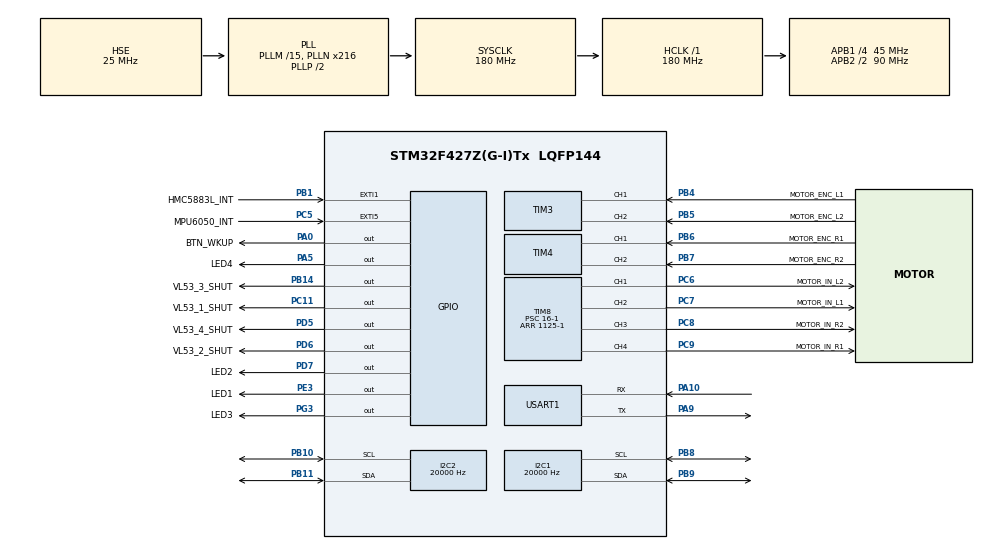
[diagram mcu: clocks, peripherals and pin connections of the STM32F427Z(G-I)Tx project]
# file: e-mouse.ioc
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Dma.I2C1_RX.4.Direction=DMA_PERIPH_TO_MEMORY
Dma.I2C1_RX.4.FIFOMode=DMA_FIFOMODE_DISABLE
Dma.I2C1_RX.4.Instance=DMA1_Stream0
Dma.I2C1_RX.4.MemDataAlignment=DMA_MDATAALIGN_BYTE
Dma.I2C1_RX.4.MemInc=DMA_MINC_ENABLE
Dma.I2C1_RX.4.Mode=DMA_NORMAL
Dma.I2C1_RX.4.PeriphDataAlignment=DMA_PDATAALIGN_BYTE
Dma.I2C1_RX.4.PeriphInc=DMA_PINC_DISABLE
Dma.I2C1_RX.4.Priority=DMA_PRIORITY_HIGH
Dma.I2C1_TX.5.Direction=DMA_MEMORY_TO_PERIPH
Dma.I2C1_TX.5.FIFOMode=DMA_FIFOMODE_DISABLE
Dma.I2C1_TX.5.Instance=DMA1_Stream6
Dma.I2C1_TX.5.MemDataAlignment=DMA_MDATAALIGN_BYTE
Dma.I2C1_TX.5.MemInc=DMA_MINC_ENABLE
Dma.I2C1_TX.5.Mode=DMA_NORMAL
Dma.I2C1_TX.5.PeriphDataAlignment=DMA_PDATAALIGN_BYTE
Dma.I2C1_TX.5.PeriphInc=DMA_PINC_DISABLE
Dma.I2C1_TX.5.Priority=DMA_PRIORITY_HIGH
Dma.I2C2_RX.0.Direction=DMA_PERIPH_TO_MEMORY
Dma.I2C2_RX.0.FIFOMode=DMA_FIFOMODE_DISABLE
Dma.I2C2_RX.0.Instance=DMA1_Stream2
Dma.I2C2_RX.0.MemDataAlignment=DMA_MDATAALIGN_BYTE
Dma.I2C2_RX.0.MemInc=DMA_MINC_ENABLE
Dma.I2C2_RX.0.Mode=DMA_NORMAL
Dma.I2C2_RX.0.PeriphDataAlignment=DMA_PDATAALIGN_BYTE
Dma.I2C2_RX.0.PeriphInc=DMA_PINC_DISABLE
Dma.I2C2_RX.0.Priority=DMA_PRIORITY_HIGH
Dma.I2C2_TX.1.Direction=DMA_MEMORY_TO_PERIPH
Dma.I2C2_TX.1.FIFOMode=DMA_FIFOMODE_DISABLE
Dma.I2C2_TX.1.Instance=DMA1_Stream7
Dma.I2C2_TX.1.MemDataAlignment=DMA_MDATAALIGN_BYTE
Dma.I2C2_TX.1.MemInc=DMA_MINC_ENABLE
Dma.I2C2_TX.1.Mode=DMA_NORMAL
Dma.I2C2_TX.1.PeriphDataAlignment=DMA_PDATAALIGN_BYTE
Dma.I2C2_TX.1.PeriphInc=DMA_PINC_DISABLE
Dma.I2C2_TX.1.Priority=DMA_PRIORITY_HIGH
Dma.Request0=I2C2_RX
Dma.Request1=I2C2_TX
Dma.Request2=USART1_RX
Dma.Request3=USART1_TX
Dma.Request4=I2C1_RX
Dma.Request5=I2C1_TX
Dma.USART1_RX.2.Direction=DMA_PERIPH_TO_MEMORY
Dma.USART1_RX.2.FIFOMode=DMA_FIFOMODE_DISABLE
Dma.USART1_RX.2.Instance=DMA2_Stream2
Dma.USART1_RX.2.MemDataAlignment=DMA_MDATAALIGN_BYTE
Dma.USART1_RX.2.MemInc=DMA_MINC_ENABLE
Dma.USART1_RX.2.Mode=DMA_NORMAL
Dma.USART1_RX.2.PeriphDataAlignment=DMA_PDATAALIGN_BYTE
Dma.USART1_RX.2.PeriphInc=DMA_PINC_DISABLE
Dma.USART1_RX.2.Priority=DMA_PRIORITY_LOW
Dma.USART1_TX.3.Direction=DMA_MEMORY_TO_PERIPH
Dma.USART1_TX.3.FIFOMode=DMA_FIFOMODE_DISABLE
Dma.USART1_TX.3.Instance=DMA2_Stream7
Dma.USART1_TX.3.MemDataAlignment=DMA_MDATAALIGN_BYTE
Dma.USART1_TX.3.MemInc=DMA_MINC_ENABLE
Dma.USART1_TX.3.Mode=DMA_NORMAL
Dma.USART1_TX.3.PeriphDataAlignment=DMA_PDATAALIGN_BYTE
Dma.USART1_TX.3.PeriphInc=DMA_PINC_DISABLE
Dma.USART1_TX.3.Priority=DMA_PRIORITY_LOW
FREERTOS.Tasks01=defaultTask,24,2048,StartDefaultTask,Default,NULL,Dynamic,NULL,NULL
FREERTOS.configENABLE_FPU=1
FREERTOS.configTIMER_TASK_STACK_DEPTH=512
FREERTOS.configUSE_PREEMPTION=0
I2C1.Analog_Filter=I2C_ANALOGFILTER_ENABLE
I2C1.ClockSpeed=20000
I2C1.I2C_Coeff_DF=15
I2C1.I2C_Mode=I2C_Standard
I2C2.ClockSpeed=20000
I2C2.I2C_Coeff_DF=15
I2C2.I2C_Mode=I2C_Standard
Mcu.Family=STM32F4
Mcu.Name=STM32F427Z(G-I)Tx
Mcu.Package=LQFP144
NVIC.DMA1_Stream0_IRQn=true\:5\:0\:false\:false\:true\:true\:false\:true\:true
NVIC.DMA1_Stream2_IRQn=true\:5\:0\:false\:false\:true\:true\:false\:true\:true
NVIC.DMA1_Stream6_IRQn=true\:5\:0\:false\:false\:true\:true\:false\:true\:true
NVIC.DMA1_Stream7_IRQn=true\:5\:0\:false\:false\:true\:true\:false\:true\:true
NVIC.DMA2_Stream2_IRQn=true\:5\:0\:false\:false\:true\:true\:false\:true\:true
NVIC.DMA2_Stream7_IRQn=true\:5\:0\:false\:false\:true\:true\:false\:true\:true
NVIC.EXTI1_IRQn=true\:5\:0\:false\:false\:true\:true\:true\:true\:true
NVIC.EXTI9_5_IRQn=true\:5\:0\:false\:false\:true\:true\:true\:true\:true
NVIC.I2C1_ER_IRQn=true\:5\:0\:false\:false\:true\:true\:true\:true\:true
NVIC.I2C1_EV_IRQn=true\:5\:0\:false\:false\:true\:true\:true\:true\:true
NVIC.I2C2_ER_IRQn=true\:5\:0\:false\:false\:true\:true\:true\:true\:true
NVIC.I2C2_EV_IRQn=true\:5\:0\:false\:false\:true\:true\:true\:true\:true
NVIC.PriorityGroup=NVIC_PRIORITYGROUP_4
NVIC.TIM1_UP_TIM10_IRQn=true\:15\:0\:false\:false\:true\:false\:false\:true\:true
NVIC.TIM3_IRQn=true\:5\:0\:false\:false\:true\:true\:true\:true\:true
NVIC.TIM4_IRQn=true\:5\:0\:false\:false\:true\:true\:true\:true\:true
NVIC.TimeBase=TIM1_UP_TIM10_IRQn
NVIC.TimeBaseIP=TIM1
NVIC.USART1_IRQn=true\:5\:0\:false\:false\:true\:true\:true\:true\:true
PA0/WKUP.GPIO_Label=BTN_WKUP
PA0/WKUP.Signal=GPIO_Output
PA10.Mode=Asynchronous
PA10.Signal=USART1_RX
PA13.Mode=Serial_Wire
PA13.Signal=SYS_JTMS-SWDIO
PA14.Mode=Serial_Wire
PA14.Signal=SYS_JTCK-SWCLK
PA5.GPIO_Label=LED4
PA5.Signal=GPIO_Output
PA9.Mode=Asynchronous
PA9.Signal=USART1_TX
PB1.GPIO_Label=HMC5883L_INT
PB1.GPIO_ModeDefaultEXTI=GPIO_MODE_IT_FALLING
PB1.GPIO_PuPd=GPIO_PULLUP
PB1.Signal=GPXTI1
PB10.GPIO_Pu=GPIO_NOPULL
PB10.GPIO_Speed=GPIO_SPEED_FREQ_LOW
PB10.Mode=I2C
PB10.Signal=I2C2_SCL
PB11.GPIO_Pu=GPIO_NOPULL
PB11.GPIO_Speed=GPIO_SPEED_FREQ_LOW
PB11.Mode=I2C
PB11.Signal=I2C2_SDA
PB14.GPIO_Label=VL53_3_SHUT
PB14.Signal=GPIO_Output
PB4.GPIO_Label=MOTOR_ENC_L1
PB4.Signal=S_TIM3_CH1
PB5.GPIO_Label=MOTOR_ENC_L2
PB5.Signal=S_TIM3_CH2
PB6.GPIO_Label=MOTOR_ENC_R1
PB6.Signal=S_TIM4_CH1
PB7.GPIO_Label=MOTOR_ENC_R2
PB7.Signal=S_TIM4_CH2
PB8.GPIO_Pu=GPIO_PULLUP
PB8.GPIO_Speed=GPIO_SPEED_FREQ_LOW
PB8.Mode=I2C
PB8.Signal=I2C1_SCL
PB9.GPIO_Pu=GPIO_PULLUP
PB9.GPIO_Speed=GPIO_SPEED_FREQ_LOW
PB9.Mode=I2C
PB9.Signal=I2C1_SDA
PC11.GPIO_Label=VL53_1_SHUT
PC11.Signal=GPIO_Output
PC5.GPIO_Label=MPU6050_INT
PC5.GPIO_ModeDefaultEXTI=GPIO_MODE_IT_FALLING
PC5.GPIO_PuPd=GPIO_PULLUP
PC5.Signal=GPXTI5
PC6.GPIO_Label=MOTOR_IN_L2
PC6.Signal=S_TIM8_CH1
PC7.GPIO_Label=MOTOR_IN_L1
PC7.Signal=S_TIM8_CH2
PC8.GPIO_Label=MOTOR_IN_R2
PC8.Signal=S_TIM8_CH3
PC9.GPIO_Label=MOTOR_IN_R1
PC9.Signal=S_TIM8_CH4
PD5.GPIO_Label=VL53_4_SHUT
PD5.Signal=GPIO_Output
PD6.GPIO_Label=VL53_2_SHUT
PD6.Signal=GPIO_Output
PD7.GPIO_Label=LED2
PD7.Signal=GPIO_Output
PE3.GPIO_Label=LED1
PE3.Signal=GPIO_Output
PG3.GPIO_Label=LED3
PG3.PinState=GPIO_PIN_SET
PG3.Signal=GPIO_Output
PH0/OSC_IN.Mode=HSE-External-Oscillator
PH0/OSC_IN.Signal=RCC_OSC_IN
PH1/OSC_OUT.Mode=HSE-External-Oscillator
PH1/OSC_OUT.Signal=RCC_OSC_OUT
ProjectManager.HeapSize=0x200
ProjectManager.StackSize=0x400
ProjectManager.TargetToolchain=Makefile
RCC.48MHZClocksFreq_Value=90000000
RCC.AHBFreq_Value=180000000
RCC.APB1CLKDivider=RCC_HCLK_DIV4
RCC.APB1Freq_Value=45000000
RCC.APB1TimFreq_Value=90000000
RCC.APB2CLKDivider=RCC_HCLK_DIV2
RCC.APB2Freq_Value=90000000
RCC.APB2TimFreq_Value=180000000
RCC.CortexFreq_Value=180000000
RCC.HCLKFreq_Value=180000000
RCC.HSE_VALUE=25000000
RCC.HSI_VALUE=16000000
RCC.LSE_VALUE=32768
RCC.PLLM=15
RCC.PLLN=216
RCC.PLLSourceVirtual=RCC_PLLSOURCE_HSE
RCC.SYSCLKFreq_VALUE=180000000
RCC.SYSCLKSource=RCC_SYSCLKSOURCE_PLLCLK
RCC.VCOOutputFreq_Value=360000000
SH.S_TIM3_CH1.0=TIM3_CH1,Encoder_Interface
SH.S_TIM3_CH2.0=TIM3_CH2,Encoder_Interface
SH.S_TIM4_CH1.0=TIM4_CH1,Encoder_Interface
SH.S_TIM4_CH2.0=TIM4_CH2,Encoder_Interface
SH.S_TIM8_CH1.0=TIM8_CH1,PWM Generation1 CH1
SH.S_TIM8_CH2.0=TIM8_CH2,PWM Generation2 CH2
SH.S_TIM8_CH3.0=TIM8_CH3,PWM Generation3 CH3
SH.S_TIM8_CH4.0=TIM8_CH4,PWM Generation4 CH4
TIM3.AutoReloadPreload=TIM_AUTORELOAD_PRELOAD_ENABLE
TIM3.EncoderMode=TIM_ENCODERMODE_TI12
TIM3.IC1Filter=15
TIM3.IC2Filter=15
TIM4.AutoReloadPreload=TIM_AUTORELOAD_PRELOAD_ENABLE
TIM4.EncoderMode=TIM_ENCODERMODE_TI12
TIM4.IC1Filter=15
TIM4.IC2Filter=15
TIM8.AutoReloadPreload=TIM_AUTORELOAD_PRELOAD_ENABLE
TIM8.Channel-PWM\ Generation1\ CH1=TIM_CHANNEL_1
TIM8.Channel-PWM\ Generation2\ CH2=TIM_CHANNEL_2
TIM8.Channel-PWM\ Generation3\ CH3=TIM_CHANNEL_3
TIM8.Channel-PWM\ Generation4\ CH4=TIM_CHANNEL_4
TIM8.Period=1125-1
TIM8.Prescaler=16-1
USART1.VirtualMode=VM_ASYNC
VP_FREERTOS_VS_CMSIS_V2.Mode=CMSIS_V2
VP_SYS_VS_tim1.Mode=TIM1
VP_TIM8_VS_ClockSourceINT.Mode=Internal
board=custom

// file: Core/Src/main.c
/* USER CODE BEGIN Header */
/**
 ******************************************************************************
 * @file           : main.c
 * @brief          : Main program body
 ******************************************************************************
 * @attention
 *
 * Copyright (c) 2023 STMicroelectronics.
 * All rights reserved.
 *
 * This software is licensed under terms that can be found in the LICENSE file
 * in the root directory of this software component.
 * If no LICENSE file comes with this software, it is provided AS-IS.
 *
 ******************************************************************************
 */
/* USER CODE END Header */
#include "main.h"
#include "cmsis_os.h"
#include "dma.h"
#include "i2c.h"
#include "tim.h"
#include "usart.h"
#include "gpio.h"

void SystemClock_Config(void);
void MX_FREERTOS_Init(void);

int main(void)
{

  /* MCU Configuration--------------------------------------------------------*/

  /* Reset of all peripherals, Initializes the Flash interface and the Systick. */
  HAL_Init();

  /* Configure the system clock */
  SystemClock_Config();

  /* Initialize all configured peripherals */
  MX_GPIO_Init();
  MX_DMA_Init();
  MX_I2C1_Init();
  MX_I2C2_Init();
  MX_TIM8_Init();
  MX_TIM3_Init();
  MX_TIM4_Init();
  MX_USART1_UART_Init();

  /* Init scheduler */
  osKernelInitialize();  /* Call init function for freertos objects (in freertos.c) */
  MX_FREERTOS_Init();

  /* Start scheduler */
  osKernelStart();
  /* We should never get here as control is now taken by the scheduler */
  /* Infinite loop */
  while (1)
  {

    }
}

void SystemClock_Config(void)
{
  RCC_OscInitTypeDef RCC_OscInitStruct = {0};
  RCC_ClkInitTypeDef RCC_ClkInitStruct = {0};

  /** Configure the main internal regulator output voltage
  */
  __HAL_RCC_PWR_CLK_ENABLE();
  __HAL_PWR_VOLTAGESCALING_CONFIG(PWR_REGULATOR_VOLTAGE_SCALE1);

  /** Initializes the RCC Oscillators according to the specified parameters
  * in the RCC_OscInitTypeDef structure.
  */
  RCC_OscInitStruct.OscillatorType = RCC_OSCILLATORTYPE_HSE;
  RCC_OscInitStruct.HSEState = RCC_HSE_ON;
  RCC_OscInitStruct.PLL.PLLState = RCC_PLL_ON;
  RCC_OscInitStruct.PLL.PLLSource = RCC_PLLSOURCE_HSE;
  RCC_OscInitStruct.PLL.PLLM = 15;
  RCC_OscInitStruct.PLL.PLLN = 216;
  RCC_OscInitStruct.PLL.PLLP = RCC_PLLP_DIV2;
  RCC_OscInitStruct.PLL.PLLQ = 4;
  if (HAL_RCC_OscConfig(&RCC_OscInitStruct) != HAL_OK)
  {
    Error_Handler();
  }

  /** Activate the Over-Drive mode
  */
  if (HAL_PWREx_EnableOverDrive() != HAL_OK)
  {
    Error_Handler();
  }

  /** Initializes the CPU, AHB and APB buses clocks
  */
  RCC_ClkInitStruct.ClockType = RCC_CLOCKTYPE_HCLK|RCC_CLOCKTYPE_SYSCLK
                              |RCC_CLOCKTYPE_PCLK1|RCC_CLOCKTYPE_PCLK2;
  RCC_ClkInitStruct.SYSCLKSource = RCC_SYSCLKSOURCE_PLLCLK;
  RCC_ClkInitStruct.AHBCLKDivider = RCC_SYSCLK_DIV1;
  RCC_ClkInitStruct.APB1CLKDivider = RCC_HCLK_DIV4;
  RCC_ClkInitStruct.APB2CLKDivider = RCC_HCLK_DIV2;

  if (HAL_RCC_ClockConfig(&RCC_ClkInitStruct, FLASH_LATENCY_5) != HAL_OK)
  {
    Error_Handler();
  }
}

/* USER CODE BEGIN 4 */
void HAL_TIM_PeriodElapsedCallback_motor(TIM_HandleTypeDef *htim);
/* USER CODE END 4 */

void HAL_TIM_PeriodElapsedCallback(TIM_HandleTypeDef *htim)
{
  if (htim->Instance == TIM1) {
    HAL_IncTick();
  }
  /* USER CODE BEGIN Callback 1 */
  else{
    HAL_TIM_PeriodElapsedCallback_motor(htim);
  }

  /* USER CODE END Callback 1 */
}

void Error_Handler(void)
{
    __disable_irq();
    while (1)
    {
    }
}

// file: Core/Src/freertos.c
/* USER CODE BEGIN Header */
/**
  ******************************************************************************
  * File Name          : freertos.c
  * Description        : Code for freertos applications
  ******************************************************************************
  * @attention
  *
  * Copyright (c) 2023 STMicroelectronics.
  * All rights reserved.
  *
  * This software is licensed under terms that can be found in the LICENSE file
  * in the root directory of this software component.
  * If no LICENSE file comes with this software, it is provided AS-IS.
  *
  ******************************************************************************
  */
/* USER CODE END Header */

#include "FreeRTOS.h"
#include "task.h"
#include "main.h"
#include "cmsis_os.h"

/* USER CODE BEGIN Includes */
#include "bsp_tasks.h"
/* USER CODE END Includes */

/* Definitions for defaultTask */
osThreadId_t defaultTaskHandle;
const osThreadAttr_t defaultTask_attributes = {
  .name = "defaultTask",
  .stack_size = 2048 * 4,
  .priority = (osPriority_t) osPriorityNormal,
};

void StartDefaultTask(void *argument);

void MX_FREERTOS_Init(void); /* (MISRA C 2004 rule 8.1) */

void MX_FREERTOS_Init(void) {

  /* Create the thread(s) */
  /* creation of defaultTask */
  defaultTaskHandle = osThreadNew(StartDefaultTask, NULL, &defaultTask_attributes);

  /* USER CODE BEGIN RTOS_THREADS */
  bsp_tasks_init();
  /* USER CODE END RTOS_THREADS */

}

void StartDefaultTask(void *argument)
{
  /* USER CODE BEGIN StartDefaultTask */
  /* Infinite loop */
  for(;;)
  {
    bsp_task_idle();
  }
  /* USER CODE END StartDefaultTask */
}
